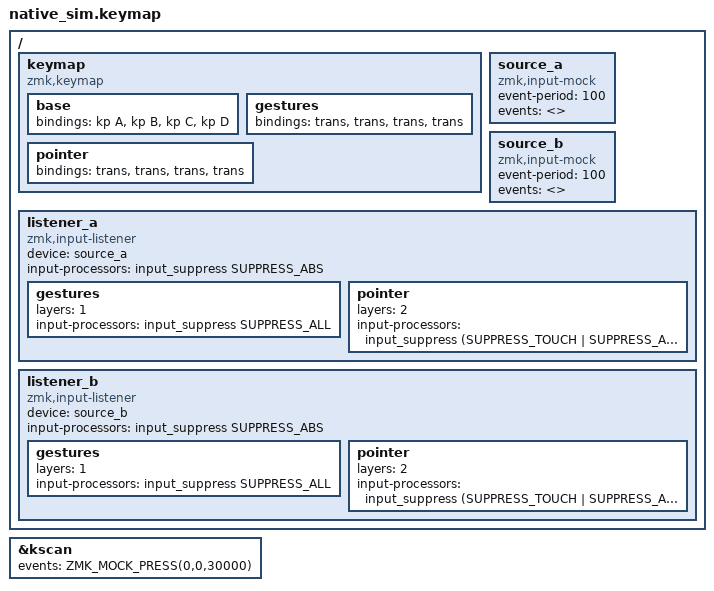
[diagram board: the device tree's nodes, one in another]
#include <behaviors.dtsi>
#include <dt-bindings/zmk/keys.h>
#include <dt-bindings/zmk/kscan_mock.h>
#include <zmk-input-suppress/input_processor_suppress.dtsi>
/ {
 keymap {
  compatible = "zmk,keymap";
  base { bindings = <&kp A &kp B &kp C &kp D>; };
  gestures { bindings = <&trans &trans &trans &trans>; };
  pointer { bindings = <&trans &trans &trans &trans>; };
 };
 source_a: source_a { compatible = "zmk,input-mock"; event-period = <100>; events = <>; };
 source_b: source_b { compatible = "zmk,input-mock"; event-period = <100>; events = <>; };
 listener_a: listener_a {
  compatible = "zmk,input-listener"; device = <&source_a>;
  input-processors = <&input_suppress SUPPRESS_ABS>;
  gestures { layers = <1>; input-processors = <&input_suppress SUPPRESS_ALL>; };
  pointer { layers = <2>; input-processors = <&input_suppress (SUPPRESS_TOUCH | SUPPRESS_ABS)>; };
 };
 listener_b: listener_b {
  compatible = "zmk,input-listener"; device = <&source_b>;
  input-processors = <&input_suppress SUPPRESS_ABS>;
  gestures { layers = <1>; input-processors = <&input_suppress SUPPRESS_ALL>; };
  pointer { layers = <2>; input-processors = <&input_suppress (SUPPRESS_TOUCH | SUPPRESS_ABS)>; };
 };
};
&kscan { events = <ZMK_MOCK_PRESS(0,0,30000)>; };
